# ATmega16U4 register map
Vendor: Atmel; File version: 1.0
CPU: other r0p0, little endian, no MPU, no FPU, 4 interrupt priority bits
Registers are 8-bit, read-write, reset 0x0 unless marked. A register's access mark holds for its fields unless they carry their own. Offsets are from the block's base; [hi:lo] are bit positions; {n}, {i} and the like mark numbered series; 'fields as' and 'values as' point back to an identical list.

## EEPROM
Base 0x0080003F
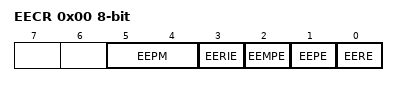
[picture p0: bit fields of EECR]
0x00 EECR — EEPROM Control Register
  [5:4] EEPM — EEPROM Programming Mode Bits
    0=ERASE_AND_WRITE_IN_ONE_OPERATION; 1=ERASE_ONLY; 2=WRITE_ONLY
  [3] EERIE — EEPROM Ready Interrupt Enable
  [2] EEMPE — EEPROM Master Write Enable
  [1] EEPE — EEPROM Write Enable
  [0] EERE — EEPROM Read Enable
0x01 EEDR — EEPROM Data Register
  [7:0] EEDR — EEPROM Data Bits
0x02 EEAR 16-bit (reset mask 0xFF) — EEPROM Address Register Low Bytes
  [11:0] EEAR — EEPROM Address Bits

## EXINT — External Interrupts
Base 0x0080003B
0x00 PCIFR — Pin Change Interrupt Flag Register (read-only for debugger)
  [0] PCIF0 — Pin Change Interrupt Flag 0
0x01 EIFR — External Interrupt Flag Register (read-only for debugger)
  [7:0] INTF — External Interrupt Flags
0x02 EIMSK — External Interrupt Mask Register
  [7:0] INT — External Interrupt Request 7 Enable
0x2D PCICR — Pin Change Interrupt Control Register
  [0] PCIE0 — Pin Change Interrupt Enable 0
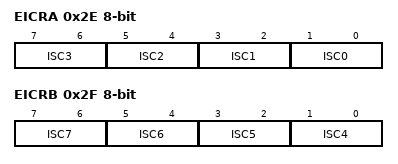
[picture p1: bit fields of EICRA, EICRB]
0x2E EICRA — External Interrupt Control Register A
  [all] fields
    0=LOW_LEVEL_OF_INTX; 1=ANY_LOGICAL_CHANGE_OF_INTX; 2=FALLING_EDGE_OF_INTX; 3=RISING_EDGE_OF_INTX
  [2n+1:2n] ISC{n} (n=0..3) — External Interrupt Sense Control Bit
0x2F EICRB — External Interrupt Control Register B
  [all] fields
    values as the fields of EICRA
  [2n-7:2n-8] ISC{n} (n=4..7) — External Interrupt 7-4 Sense Control Bit
0x30 PCMSK0 — Pin Change Mask Register 0
  [7:0] PCINT — Pin Change Mask 0

## JTAG — JTAG Interface
Base 0x00800051
0x00 OCDR — On-Chip Debug Related Register in I/O Memory (write-only for debugger)
0x03 MCUSR — MCU Status Register (read-only for debugger)
  [4] JTRF — JTAG Reset Flag
0x04 MCUCR — MCU Control Register
  [7] JTD — JTAG Interface Disable

## PLL — Phase Locked Loop
Base 0x00800049
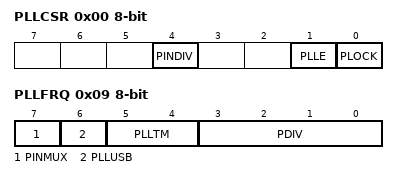
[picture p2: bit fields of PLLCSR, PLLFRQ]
0x00 PLLCSR — PLL Status and Control register
  [4] PINDIV — PLL prescaler Bit 2
  [1] PLLE — PLL Enable Bit
  [0] PLOCK — PLL Lock Status Bit
0x09 PLLFRQ — PLL Frequency Control Register
  [7] PINMUX, [6] PLLUSB, [5:4] PLLTM, [3:0] PDIV

## PORTB — I/O Port
Base 0x00800023
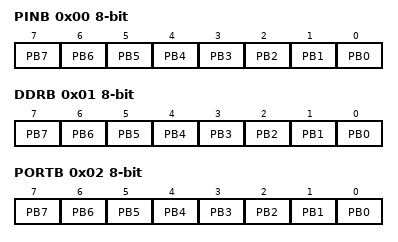
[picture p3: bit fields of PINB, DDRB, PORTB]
0x00 PINB — Port B Input Pins (read-only for debugger)
  [n] PB{n} (n=0..7) — Pin B{n}
0x01 DDRB — Port B Data Direction Register
  [n] PB{n} (n=0..7) — Pin B{n}
0x02 PORTB — Port B Data Register
  [n] PB{n} (n=0..7) — Pin B{n}

## PORTC — I/O Port
Base 0x00800026
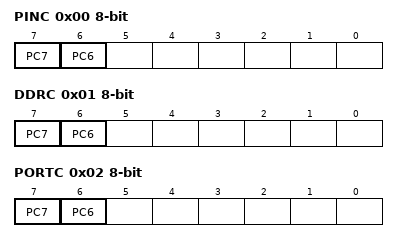
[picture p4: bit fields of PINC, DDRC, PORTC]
0x00 PINC — Port C Input Pins (read-only for debugger)
  [7] PC7 — Pin C7
  [6] PC6 — Pin C6
0x01 DDRC — Port C Data Direction Register
  [7] PC7 — Pin C7
  [6] PC6 — Pin C6
0x02 PORTC — Port C Data Register
  [7] PC7 — Pin C7
  [6] PC6 — Pin C6

## PORTD — I/O Port
Base 0x00800029
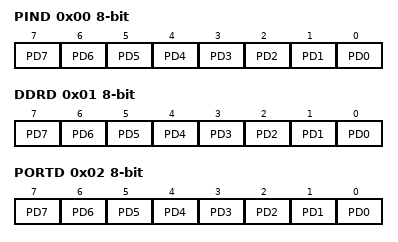
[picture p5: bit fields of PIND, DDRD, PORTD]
0x00 PIND — Port D Input Pins (read-only for debugger)
  [n] PD{n} (n=0..7) — Pin D{n}
0x01 DDRD — Port D Data Direction Register
  [n] PD{n} (n=0..7) — Pin D{n}
0x02 PORTD — Port D Data Register
  [n] PD{n} (n=0..7) — Pin D{n}

## PORTE — I/O Port
Base 0x0080002C
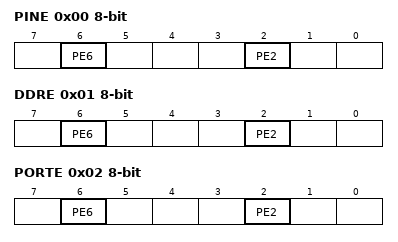
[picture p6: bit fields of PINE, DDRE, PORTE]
0x00 PINE — Input Pins, Port E (read-only for debugger)
  [6] PE6 — Pin E6
  [2] PE2 — Pin E2
0x01 DDRE — Data Direction Register, Port E
  [6] PE6 — Pin E6
  [2] PE2 — Pin E2
0x02 PORTE — Data Register, Port E
  [6] PE6 — Pin E6
  [2] PE2 — Pin E2

## PORTF — I/O Port
Base 0x0080002F
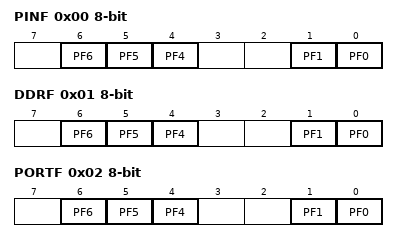
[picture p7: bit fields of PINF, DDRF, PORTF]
0x00 PINF — Input Pins, Port F (read-only for debugger)
  [6] PF6 — Pin F6
  [5] PF5 — Pin F5
  [4] PF4 — Pin F4
  [1] PF1 — Pin F1
  [0] PF0 — Pin F0
0x01 DDRF — Data Direction Register, Port F
  fields as PINF
0x02 PORTF — Data Register, Port F
  fields as PINF

## SPI — Serial Peripheral Interface
Base 0x0080004C
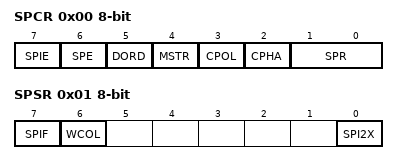
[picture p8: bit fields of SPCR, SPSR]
0x00 SPCR — SPI Control Register
  [7] SPIE — SPI Interrupt Enable
  [6] SPE — SPI Enable
  [5] DORD — Data Order
  [4] MSTR — Master/Slave Select
  [3] CPOL — Clock polarity
  [2] CPHA — Clock Phase
  [1:0] SPR — SPI Clock Rate Selects
    0=FOSC_4; 1=FOSC_16; 3=FOSC_128
0x01 SPSR — SPI Status Register (read-only for debugger)
  [7] SPIF — SPI Interrupt Flag
  [6] WCOL — Write Collision Flag
  [0] SPI2X — Double SPI Speed Bit
0x02 SPDR — SPI Data Register (write-only for debugger)
  [7:0] SPDR — SPI Data bits
